# JN5179 register map
Vendor: NXP; Series: JN517x; File version: 20150316
NXP JN5179 Wireless MCU: Cortex-M3 Microcontroller with 512KB Flash, 32KB RAM, IEEE802.15.4 Radio (refer to http://www.nxp.com/techzones/wireless-connectivity/overview.html for more)
CPU: CM3 r2p1, little endian, no MPU, no FPU, 4 interrupt priority bits
Registers are 32-bit, read-write, reset 0x0 unless marked. A register's access mark holds for its fields unless they carry their own. Offsets are from the block's base; lines under a group give offsets from that group; [hi:lo] are bit positions; {n}, {i} and the like mark numbered series; 'fields as' and 'values as' point back to an identical list; <NAME> marks a mode.

## Memory map
0x40000000 SYS_CTRL size 0x200 — System Controller
0x40006000 Timer0 size 0x20 — 32 bit Timer / Counter
0x40007000 Timer1 size 0x20
0x4000B000 PWM1 size 0x20
0x4000C000 PWM2 size 0x30
0x4000D000 PWM3 size 0x20
0x4000E000 PWM4 size 0x20
0x4000F000 PWM5 size 0x20
0x40010000 PWM6 size 0x20
0x40011000 TimerAP size 0x20

## Timer0 — 32 bit Timer / Counter
Base 0x40006000
Same registers: Timer1 0x40007000, PWM1 0x4000B000, PWM3 0x4000D000, PWM4 0x4000E000, PWM5 0x4000F000, PWM6 0x40010000, TimerAP 0x40011000
0x00 CTR — Counter Value
0x04 LO (reset mask 0xFFFF) — Defines the point during the period at which the output goes high i.e. the low time.
0x08 PERIOD (reset mask 0xFFFF) — Defines the total period of the counter.
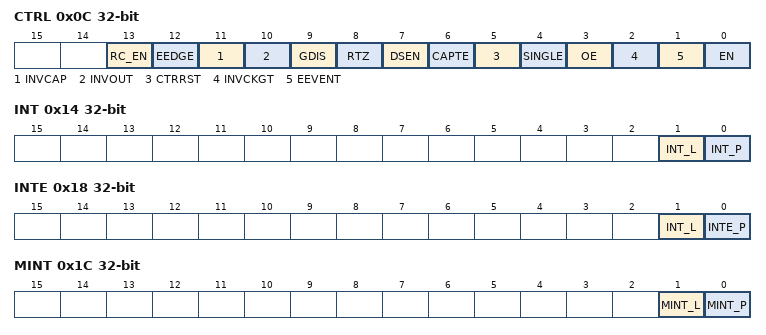
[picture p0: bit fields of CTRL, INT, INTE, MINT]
0x0C CTRL (reset mask 0x1FFF) — Control Register
  [13] RC_EN — Enable Intra-red transmitter (PWM2 timer only)
    0=RC_Disabled (Infra-red transmitter disabled); 1=RC_Enabled (Infra-red transmitter enabled)
  [12] EEDGE — Counter event edge select
    0=Edge_Positive (Use positive edge for counter); 1=Edge_Both (Use both edges for counter)
  [11] INVCAP — Invert capture input
    0=Capture_Normal (Capture input is not inverted); 1=Capture_Inverted (Capture input is inverted)
  [10] INVOUT — Invert PWM output
    0=PWM_Normal (PWM Output is not inverted (Mandatory for Delta-Sigma Mode)); 1=PWM_Inverted (PWM Output is inverted)
  [9] GDIS — External gate disable
    0=Gate_Enabled (External gate is enabled); 1=Gate_Disabled (External gate is ignored)
  [8] RTZ — Return to Zero in DS Mode
    0=RTZ_Disabled (Do not return to zero in Delta-Sigma Mode); 1=RTZ_Enabled (Return to zero in Delta-Sigma Mode)
  [7] DSEN — Enable Delta-Sigma Mode
    0=DS_Disabled (Delta-Sigma Mode is disabled); 1=DS_Enabled (Delta-Sigma Modeis enabled)
  [6] CAPTE — Enable Capture Mode
    0=Capture_Disabled (Capture Mode is disabled); 1=Capture_Enabled (Capture Mode is enabled)
  [5] CTRRST wo — Reset Counter
    0=Reserved (Write as ZERO if necessary); 1=Reset the Timer
  [4] SINGLE — Enable single shot
    0=repeat (Timer operates in repeat mode); 1=single (Timer operates in single-shot mode)
  [3] OE — Output Enable
    0=output_disabled (Output is in High-Z state); 1=output_enabled (Output is enabled for PWM and Delta-Sigma)
  [2] INVCKGT — Invert ck_gt
    0=ck_gt_normal (Do not invert ck_gt input); 1=ck_gt_invert (Invert ck_gt input)
  [1] EEVENT — External Event Select
    0=ck_gt_gate (Use ck_gt pin as gate); 1=ck_gt_event (Use ck_gt pin as event)
  [0] EN — Enable
    0=Disable (Timer is disabled and does not operate); 1=Enable (Timer is enabled and can operate)
0x10 PRE_SEL (reset mask 0x1F) — Clock divider prescale value. The prescaler divides by
0x14 INT — Interrupt Status
  [1] INT_L — End of low period
    0=INT_L_Clear (Write as zero); 1=INT_L_Asserted (Timer rising edge (end of low) interrupt occured)
  [0] INT_P — End of period
    0=INT_P_Clear (Write as zero); 1=INT_P_Asserted (Timer falling edge (end of period) interrupt occured)
0x18 INTE — Interrupt enable
  [1] INT_L — Enable end of low period interrupt
    0=INT_L_Disabled (Disable interrupt on Timer rising edge (end of low)); 1=INT_L_Enabled (Generate interrupt on Timer rising edge (end of low))
  [0] INTE_P — Enable end of period interrupt
    0=INT_P_Disabled (Disable interrupt on Timer falling edge (end of period)); 1=INT_P_Enabled (Generate interrupt on Timer falling edge (end of period))
0x1C MINT — Masked interrupt status
  [1] MINT_L — End of low period
    0=MINT_L_Clear (Write as zero); 1=MINT_L_Asserted (Timer rising edge (end of low) interrupt enabled and occured)
  [0] MINT_P — End of period
    0=MINT_P_Clear (Write as zero); 1=MINT_P_Asserted (Timer falling edge (end of period) interrupt enabled and occured)

## Notices in the file
This software is owned by NXP B.V. and/or its supplier and is protected
under applicable copyright laws. All rights are reserved. We grant You,
and any third parties, a license to use this software solely and
exclusively on NXP products [NXP Microcontrollers such as JN5179].
You, and any third parties must reproduce the copyright and warranty notice
and any other legend of ownership on each copy or partial copy of the
software.
THIS SOFTWARE IS PROVIDED BY THE COPYRIGHT HOLDERS AND CONTRIBUTORS "AS IS"
AND ANY EXPRESS OR IMPLIED WARRANTIES, INCLUDING, BUT NOT LIMITED TO, THE
IMPLIED WARRANTIES OF MERCHANTABILITY AND FITNESS FOR A PARTICULAR PURPOSE
ARE DISCLAIMED. IN NO EVENT SHALL THE COPYRIGHT HOLDER OR CONTRIBUTORS BE
LIABLE FOR ANY DIRECT, INDIRECT, INCIDENTAL, SPECIAL, EXEMPLARY, OR
CONSEQUENTIAL DAMAGES (INCLUDING, BUT NOT LIMITED TO, PROCUREMENT OF
SUBSTITUTE GOODS OR SERVICES; LOSS OF USE, DATA, OR PROFITS; OR BUSINESS
INTERRUPTION) HOWEVER CAUSED AND ON ANY THEORY OF LIABILITY, WHETHER IN
CONTRACT, STRICT LIABILITY, OR TORT (INCLUDING NEGLIGENCE OR OTHERWISE)
ARISING IN ANY WAY OUT OF THE USE OF THIS SOFTWARE, EVEN IF ADVISED OF THE
POSSIBILITY OF SUCH DAMAGE.
Copyright NXP B.V. 2015. All rights reserved
